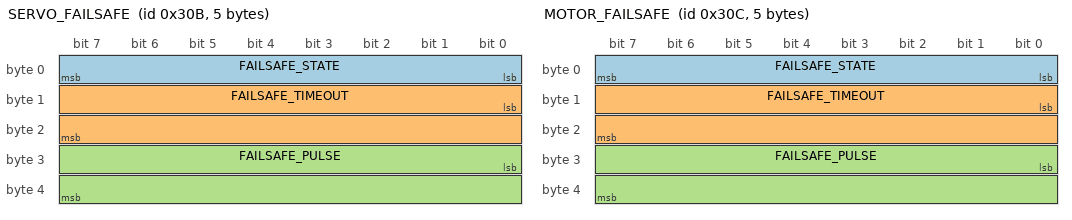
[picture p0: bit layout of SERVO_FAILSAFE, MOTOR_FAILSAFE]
VERSION ""

NS_ :

BS_:

BU_: BATTERY_MONITOR SERVO MOTOR SBUS_RECEIVER

BO_ 0x100 STEERING: 3 SBUS_RECEIVER
 SG_ STEERING_MODE M : 0|8@1+ (1,0) [0|0] "" SERVO
 SG_ STEERING_PULSE_WIDTH m0 : 8|16@1+ (1,0) [0|0] "µs" SERVO
 SG_ STEERING_ANGLE m1 : 8|16@1- (1,0) [-90|90] "degrees" SERVO

BO_ 0x101 THROTTLE: 3 SBUS_RECEIVER
 SG_ THROTTLE_MODE M : 0|8@1+ (1,0) [0|0] "" MOTOR
 SG_ THROTTLE_PULSE_WIDTH m0 : 8|16@1+ (1,0) [0|0] "µs" MOTOR

BO_ 0x102 STEERING_TRIM: 3 SBUS_RECEIVER
 SG_ STEERING_TRIM_MODE M : 0|8@1+ (1,0) [0|0] "" SERVO
 SG_ STEERING_TRIM_PULSE_WIDTH m0 : 8|16@1- (1,0) [0|0] "µs" SERVO
 SG_ STEERING_TRIM_ANGLE m1 : 8|16@1- (1,0) [-45|45] "degrees" SERVO

BO_ 0x103 THROTTLE_TRIM: 3 SBUS_RECEIVER
 SG_ THROTTLE_TRIM_MODE M : 0|8@1+ (1,0) [0|0] "" MOTOR
 SG_ THROTTLE_TRIM_PULSE_WIDTH m0 : 8|16@1- (1,0) [0|0] "µs" MOTOR

BO_ 0x104 BRAKE_POWER: 1 Vector__XXX
 SG_ POWER : 0|8@1- (1,0) [0|0] "%" Vector__XXX

BO_ 0x105 BRAKE_POSITION: 2 Vector__XXX
 SG_ POSITION : 0|16@1- (1,0) [0|0] "degrees" Vector__XXX

BO_ 0x200 BATTERY_CELL_CHARGE: 7 BATTERY_MONITOR
 SG_ CELLS M : 0|8@1+ (1,0) [0|0] "" Vector__XXX
 SG_ CELL_1_VOLTAGE m0 : 8|16@1+ (1,0) [0|0] "mV" Vector__XXX
 SG_ CELL_2_VOLTAGE m0 : 24|16@1+ (1,0) [0|0] "mV" Vector__XXX
 SG_ CELL_3_VOLTAGE m0 : 40|16@1+ (1,0) [0|0] "mV" Vector__XXX
 SG_ CELL_4_VOLTAGE m1 : 8|16@1+ (1,0) [0|0] "mV" Vector__XXX
 SG_ CELL_5_VOLTAGE m1 : 24|16@1+ (1,0) [0|0] "mV" Vector__XXX
 SG_ CELL_6_VOLTAGE m1 : 40|16@1+ (1,0) [0|0] "mV" Vector__XXX

BO_ 0x201 REGULATED_OUTPUT: 4 BATTERY_MONITOR
 SG_ REGULATED_OUTPUT_VOLTAGE : 0|16@1+ (1,0) [0|0] "mV" Vector__XXX
 SG_ REGULATED_OUTPUT_CURRENT : 16|16@1+ (1,0) [0|0] "mA" Vector__XXX

BO_ 0x202 VBAT_OUTPUT_CURRENT: 4 BATTERY_MONITOR
 SG_ VBAT_OUTPUT_CURRENT : 0|32@1+ (1,0) [0|0] "mA" Vector__XXX

BO_ 0x203 SERVO_VOLTAGE: 2 SERVO
 SG_ SERVO_VOLTAGE : 0|16@1+ (1,0) [0|0] "mV" Vector__XXX

BO_ 0x204 SERVO_CURRENT: 2 SERVO
 SG_ SERVO_CURRENT : 0|16@1+ (1,0) [0|0] "mA" Vector__XXX

BO_ 0x205 H_BRIDGE_CURRENT: 2 SERVO
 SG_ H_BRIDGE_CURRENT: 0|16@1+ (1,0) [0|0] "mA" Vector__XXX

BO_ 0x300 BATTERY_JUMPER_AND_FUSE_CONFIG: 7 Vector__XXX
 SG_ JUMPER_CONFIG : 0|8@1+ (1,0) [0|0] "" BATTERY_MONITOR
 SG_ FUSE_CONFIG : 8|8@1+ (1,0) [0|0] "" BATTERY_MONITOR
 SG_ SET_OVER_CURRENT M : 16|8@1+ (1,0) [0|0] "" BATTERY_MONITOR
 SG_ OVER_CURRENT_THRESHOLD m1 : 24|32@1+ (1,0) [0|0] "mA" BATTERY_MONITOR

BO_ 0x301 REGULATED_OUTPUT_VOLTAGE: 2 Vector__XXX
 SG_ REGULATED_OUTPUT_VOLTAGE : 0|16@1+ (1,0) [0|0] "mV" BATTERY_MONITOR

BO_ 0x302 BATTERY_OUTPUT_ON_OFF: 2 Vector__XXX
 SG_ REGULATED_OUTPUT_STATE : 0|8@1+ (1,0) [0|0] "" BATTERY_MONITOR
 SG_ MAIN_POWER_OUTPUT_STATE : 8|8@1+ (1,0) [0|0] "" BATTERY_MONITOR

BO_ 0x303 BATTERY_REPORT_FREQUENCY: 4 Vector__XXX
 SG_ MONITORING_PERIOD : 0|16@1+ (1,0) [0|0] "ms" BATTERY_MONITOR
 SG_ REPORT_PERIOD : 16|16@1+ (1,0) [0|0] "ms" BATTERY_MONITOR

BO_ 0x304 BATTERY_LOW_VOLTAGE_CUTOFF: 2 Vector__XXX
 SG_ LOW_VOLTAGE_CUTOFF_THRESHOLD : 0|16@1+ (1,0) [0|0] "mV" BATTERY_MONITOR

BO_ 0x305 SERVO_SET_VOLTAGE: 2 Vector__XXX
 SG_ REQUESTED_SERVO_VOLTAGE : 0|16@1+ (1,0) [2740|10800] "mV" SERVO

BO_ 0x306 SERVO_PWM_CONFIG: 2 Vector__XXX
 SG_ PWM_FREQUENCY : 0|16@1+ (1,0) [1|333] "Hz" SERVO

BO_ 0x307 SERVO_REPORT_FREQUENCY: 4 Vector__XXX
 SG_ MEASURING_PERIOD : 0|16@1+ (1,0) [0|0] "ms" SERVO
 SG_ REPORT_PERIOD : 16|16@1+ (1,0) [0|0] "ms" SERVO

BO_ 0x308 MOTOR_PWM_CONFIG: 2 Vector__XXX
 SG_ PWM_FREQUENCY : 0|16@1+ (1,0) [1|333] "Hz" MOTOR

BO_ 0x309 SERVO_REVERSE_DIRECTION: 0 Vector__XXX

BO_ 0x30A MOTOR_REVERSE_DIRECTION: 0 Vector__XXX

BO_ 0x30B SERVO_FAILSAFE: 5 Vector__XXX
 SG_ FAILSAFE_STATE : 0|8@1+ (1,0) [0|0] "" SERVO
 SG_ FAILSAFE_TIMEOUT : 8|16@1+ (1,0) [0|0] "ms" SERVO
 SG_ FAILSAFE_PULSE : 24|16@1+ (1,0) [0|0] "µs" SERVO

BO_ 0x30C MOTOR_FAILSAFE: 5 Vector__XXX
 SG_ FAILSAFE_STATE : 0|8@1+ (1,0) [0|0] "" MOTOR
 SG_ FAILSAFE_TIMEOUT : 8|16@1+ (1,0) [0|0] "ms" MOTOR
 SG_ FAILSAFE_PULSE : 24|16@1+ (1,0) [0|0] "µs" MOTOR

BO_ 0x30D SERVO_POSITION: 2 SERVO
 SG_ SERVO_POSITION : 0|16@1- (1,0) [-90|90] "degrees" SERVO

VAL_ 0x100 STEERING_MODE 0 "PULSE_WIDTH_MODE" 1 "ANGLE_MODE" ;
VAL_ 0x101 THROTTLE_MODE 0 "PULSE_WIDTH_MODE" ;
VAL_ 0x102 STEERING_TRIM_MODE 0 "PULSE_WIDTH_MODE" 1 "ANGLE_MODE" ;
VAL_ 0x103 THROTTLE_TRIM_MODE 0 "PULSE_WIDTH_MODE" ;
VAL_ 0x200 CELLS 0 "CELLS_1_TO_3" 1 "CELLS_4_TO_6" ;
VAL_ 0x300 JUMPER_CONFIG 0 "ALL OFF" 1 "X11_ON" 2 "X12_ON" 3 "ALL_ON" ;
VAL_ 0x300 FUSE_CONFIG 0 "FUSE_50_AMPERE" 1 "FUSE_100_AMPERE"
VAL_ 0x300 SET_OVER_CURRENT 1 "SET_OVER_CURRENT" ;
VAL_ 0x302 REGULATED_OUTPUT_STATE 0 "OFF" 1 "ON" ;
VAL_ 0x302 MAIN_POWER_OUTPUT_STATE 0 "OFF" 1 "ON" ;
VAL_ 0x30B FAILSAFE_STATE 0 "OFF" 1 "ON" ;
VAL_ 0x30C FAILSAFE_STATE 0 "OFF" 1 "ON" ;
